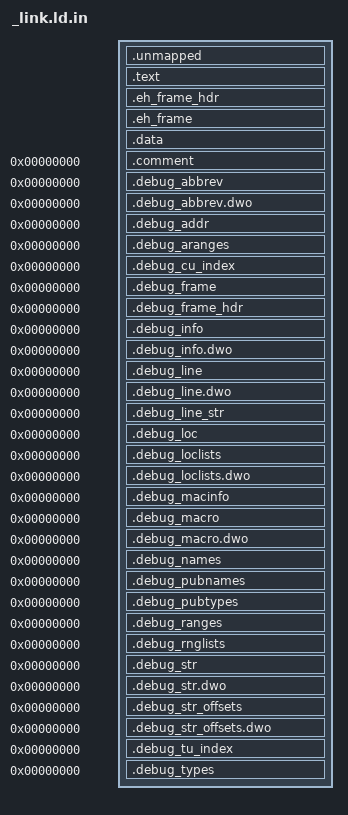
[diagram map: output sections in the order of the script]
/** PPC32 linker script
 *
 * umapped section:
 *  kernel text
 *  kernel data
 * mapped section:
 *  kernel text
 *  kernel data
 *
 */

#include <arch/boot/boot.h>
#include <arch/mm/page.h>

ENTRY(kernel_image_start)
OUTPUT_FORMAT("elf32-powerpc")
OUTPUT_ARCH("powerpc:common")

SECTIONS {
	kernel_load_address = PA2KA(0);

	.unmapped (SIZEOF_HEADERS): AT (SIZEOF_HEADERS) {
		. = ALIGN(0x100);
		KEEP(*(K_UNMAPPED_TEXT_START));
	}

	.text PA2KA(BOOT_OFFSET): AT (BOOT_OFFSET) {
		ktext_start = .;
		KEEP(*(K_TEXT_START));
		*(.text .text.*);
		ktext_end = .;
	}

	/* stack unwinding data */
	.eh_frame_hdr : {
		eh_frame_hdr_start = .;
		*(.eh_frame_hdr) *(.eh_frame_entry .eh_frame_entry.*);
		eh_frame_hdr_end = .;
	}

	.eh_frame : {
		eh_frame_start = .;
		KEEP(*(.eh_frame .eh_frame.*));
		eh_frame_end = .;
	}

	.data : {
		kdata_start = .;
		KEEP(*(K_DATA_START));
		*(.rodata .rodata.*);
		*(.data .data.*);       /* initialized data */
		*(.sdata .sdata.*);
		*(.sdata2 .sdata2.*);
		*(.sbss .sbss.*);
		*(.bss .bss.*);        /* uninitialized static variables */
		*(COMMON);      /* global variables */
		kdata_end = .;
	}

	.comment 0 : { *(.comment); }
	.debug_abbrev 0 : { *(.debug_abbrev); }
	.debug_abbrev.dwo 0 : { *(	.debug_abbrev.dwo); }
	.debug_addr 0 : { *(.debug_addr); }
	.debug_aranges 0 : { *(.debug_aranges); }
	.debug_cu_index 0 : { *(.debug_cu_index); }
	.debug_frame 0 : { *(.debug_frame); }
	.debug_frame_hdr 0 : { *(.debug_frame_hdr); }
	.debug_info 0 : { *(.debug_info); }
	.debug_info.dwo 0 : { *(.debug_info.dwo); }
	.debug_line 0 : { *(.debug_line); }
	.debug_line.dwo 0 : { *(.debug_line.dwo); }
	.debug_line_str 0 : { *(.debug_line_str); }
	.debug_loc 0 : { *(.debug_loc); }
	.debug_loclists 0 : { *(.debug_loclists); }
	.debug_loclists.dwo 0 : { *(.debug_loclists.dwo); }
	.debug_macinfo 0 : { *(.debug_macinfo); }
	.debug_macro 0 : { *(.debug_macro); }
	.debug_macro.dwo 0 : { *(.debug_macro.dwo); }
	.debug_names 0 : { *(.debug_names); }
	.debug_pubnames 0 : { *(.debug_pubnames); }
	.debug_pubtypes 0 : { *(.debug_pubtypes); }
	.debug_ranges 0 : { *(.debug_ranges); }
	.debug_rnglists 0 : { *(.debug_rnglists); }
	.debug_str 0 : { *(.debug_str); }
	.debug_str.dwo 0 : { *(.debug_str.dwo); }
	.debug_str_offsets 0 : { *(.debug_str_offsets); }
	.debug_str_offsets.dwo 0 : { *(.debug_str_offsets.dwo); }
	.debug_tu_index 0 : { *(.debug_tu_index); }
	.debug_types 0 : { *(.debug_types); }

	/DISCARD/ : {
		*(*);
	}
}
